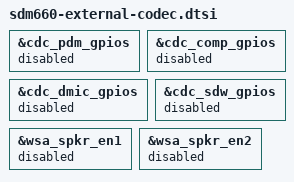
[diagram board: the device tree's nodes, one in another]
/* Copyright (c) 2017, 2019, The Linux Foundation. All rights reserved.
 *
 * This program is free software; you can redistribute it and/or modify
 * it under the terms of the GNU General Public License version 2 and
 * only version 2 as published by the Free Software Foundation.
 *
 * This program is distributed in the hope that it will be useful,
 * but WITHOUT ANY WARRANTY; without even the implied warranty of
 * MERCHANTABILITY or FITNESS FOR A PARTICULAR PURPOSE.  See the
 * GNU General Public License for more details.
 */

&cdc_pdm_gpios {
	status = "disabled";
};

&cdc_comp_gpios {
	status = "disabled";
};

&cdc_dmic_gpios {
	status = "disabled";
};

&cdc_sdw_gpios {
	status = "disabled";
};

&wsa_spkr_en1 {
	status = "disabled";
};

&wsa_spkr_en2 {
	status = "disabled";
};
